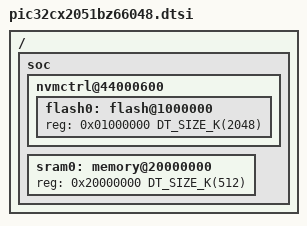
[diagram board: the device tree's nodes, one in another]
/*
 * Copyright (c) 2025 Microchip Technology Inc.
 *
 * SPDX-License-Identifier: Apache-2.0
 */

#include <mem.h>
#include <microchip/pic32c/pic32cx_bz/bz6x/common/pic32cxxbz6x.dtsi>

/ {
	soc {
		nvmctrl@44000600 {
			flash0: flash@1000000 {
				reg = <0x01000000 DT_SIZE_K(2048)>;
			};
		};

		sram0: memory@20000000 {
			reg = <0x20000000 DT_SIZE_K(512)>;
		};
	};
};
